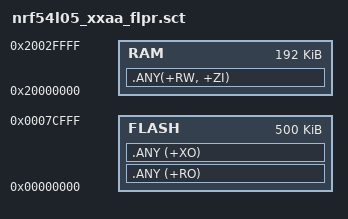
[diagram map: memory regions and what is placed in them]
LOAD 0x00000000 0x0007D000
{
    FLASH 0x00000000 0x0007D000
    {
    
        .ANY (+RO)
        .ANY (+XO)
    }

    RAM 0x20000000 0x00030000
    {
    .ANY(+RW, +ZI) ; RW data and ZI data
    }

}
